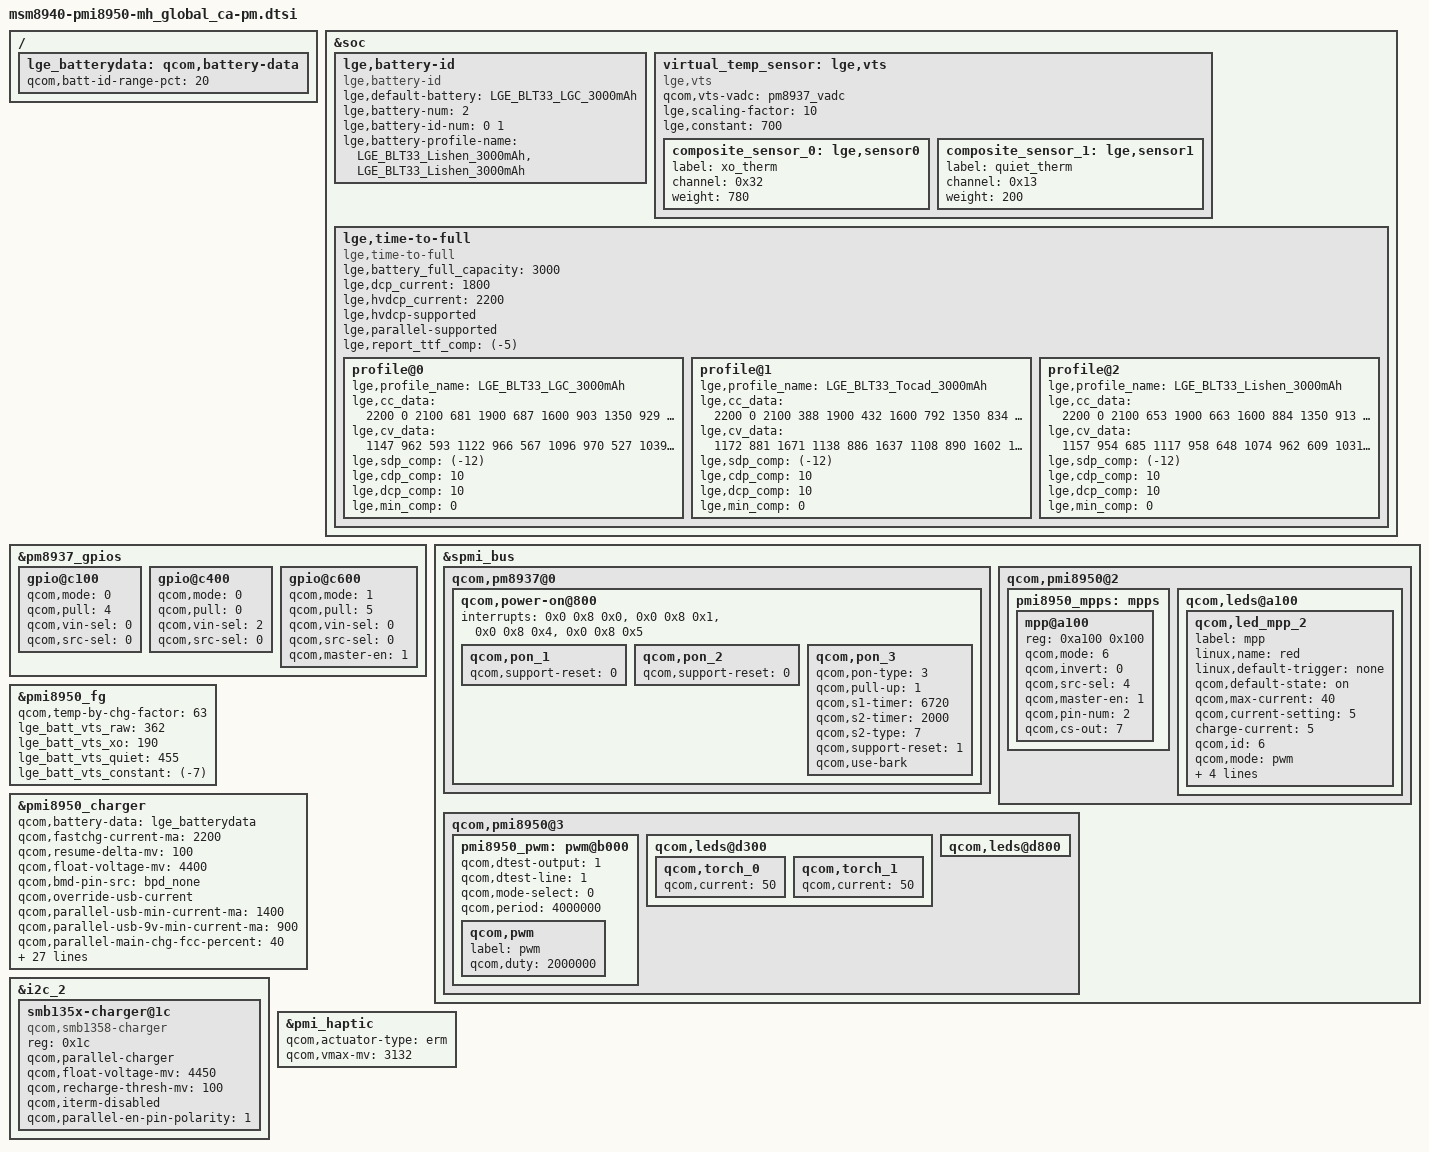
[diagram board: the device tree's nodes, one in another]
/*
 * Copyright (c) 2016, The Linux Foundation. All rights reserved.
 *
 * This program is free software; you can redistribute it and/or modify
 * it under the terms of the GNU General Public License version 2 and
 * only version 2 as published by the Free Software Foundation.
 *
 * This program is distributed in the hope that it will be useful,
 * but WITHOUT ANY WARRANTY; without even the implied warranty of
 * MERCHANTABILITY or FITNESS FOR A PARTICULAR PURPOSE.  See the
 * GNU General Public License for more details.
 */

/{
	lge_batterydata: qcom,battery-data {
		qcom,batt-id-range-pct = <20>;
		#include "../battery_profile/LGE_BLT33_LGC_3000mAh.dtsi"
		#include "../battery_profile/LGE_BLT33_Tocad_3000mAh.dtsi"
		#include "../battery_profile/LGE_BLT33_Lishen_3000mAh.dtsi"
	};
};

&soc {
	lge,battery-id{
		compatible = "lge,battery-id";
		/delete-property/ lge,restrict-mode-enabled;
		/*default battery profile*/
		lge,default-battery = "LGE_BLT33_LGC_3000mAh";
		/*Total number of combined of battery cell and battery id */
		lge,battery-num = <2>;
		/* battery id and battery profile match numbers */
		lge,battery-id-num = <0 1>;
		/* battery profile */
		lge,battery-profile-name = "LGE_BLT33_Lishen_3000mAh",
						"LGE_BLT33_Lishen_3000mAh";
	};

	/* vts = (0.78*xo_therm) + (0.2*quiet_therm) + (0.7) */
	virtual_temp_sensor: lge,vts {
		compatible = "lge,vts";
		qcom,vts-vadc = <&pm8937_vadc>;
		lge,scaling-factor= <10>;
		lge,constant = <700>;
		composite_sensor_0: lge,sensor0 {
			label = "xo_therm";
			channel = <0x32>;
			weight = <780>;
		};
		composite_sensor_1: lge,sensor1 {
			label = "quiet_therm";
			channel = <0x13>;
			weight = <200>;
		};
	};

	/* time to full */
	lge,time-to-full {
		compatible = "lge,time-to-full";
		lge,battery_full_capacity = <3000>;
		lge,dcp_current = <1800>;
		lge,hvdcp_current = <2200>;
		lge,hvdcp-supported;
		lge,parallel-supported;
		lge,report_ttf_comp = <(-5)>;
		profile@0 {
			lge,profile_name = "LGE_BLT33_LGC_3000mAh";
				    /* current  soc */
			lge,cc_data = < 2200	0
					2100	681
					1900	687
					1600	903
					1350	929
					1175	951>;
				    /* current  soc    time */
			lge,cv_data = < 1147	962	593
					1122	966	567
					1096	970	527
					1039	973	486
					993	977	442
					934	980	395
					887	983	347
					745	986	295
					787	989	241
					743	992	184
					709	995	125
					663	998	63
					645	1000	0>;
			lge,sdp_comp = <(-12)>;
			lge,cdp_comp = <10>;
			lge,dcp_comp = <10>;
			lge,min_comp = <0>;
		};
		profile@1 {
			lge,profile_name = "LGE_BLT33_Tocad_3000mAh";
				    /* current  soc */
			lge,cc_data = < 2200	0
					2100	388
					1900	432
					1600	792
					1350	834
					1175	869>;
				    /* current  soc    time */
			lge,cv_data = < 1172	881	1671
					1138	886	1637
					1108	890	1602
					1083	894	1566
					1068	898	1530
					1051	903	1493
					1021	907	1454
					992	911	1414
					962	915	1374
					937	920	1332
					906	924	1289
					878	928	1246
					739	932	1201
					823	937	1154
					795	941	1105
					767	945	1055
					748	949	1003
					728	954	951
					700	958	896
					675	962	840
					650	966	782
					624	970	722
					597	973	662
					517	977	599
					555	980	532
					529	983	464
					506	986	393
					487	989	321
					461	992	246
					442	995	167
					419	998	86
					398	1000	0>;
			lge,sdp_comp = <(-12)>;
			lge,cdp_comp = <10>;
			lge,dcp_comp = <10>;
			lge,min_comp = <0>;
		};
		profile@2 {
			lge,profile_name = "LGE_BLT33_Lishen_3000mAh";
				    /* current  soc */
			lge,cc_data = < 2200	0
					2100	653
					1900	663
					1600	884
					1350	913
					1175	937>;
				    /* current  soc    time */
			lge,cv_data = < 1157	954	685
					1117	958	648
					1074	962	609
					1031	966	570
					986	970	527
					944	973	485
					906	977	439
					856	980	393
					816	983	343
					776	986	292
					750	989	237
					622	992	182
					672	995	122
					658	998	63
					621	1000	0>;
			lge,sdp_comp = <(-12)>;
			lge,cdp_comp = <10>;
			lge,dcp_comp = <10>;
			lge,min_comp = <0>;
		};
	};
};

&pm8937_gpios {
	gpio@c100 {
		qcom,mode = <0>;
		qcom,pull = <4>;
		qcom,vin-sel = <0>;
		qcom,src-sel = <0>;
		status = "okay";
	};
	gpio@c400 {
		qcom,mode = <0>;
		qcom,pull = <0>;
		qcom,vin-sel = <2>;
		qcom,src-sel = <0>;
		status = "okay";
	};
	gpio@c600 {
		status = "okay";
		qcom,mode = <1>;
		qcom,pull = <5>;
		qcom,vin-sel = <0>;
		qcom,src-sel = <0>;
		qcom,master-en = <1>;
	};
};

&spmi_bus {
	qcom,pm8937@0 {
		qcom,power-on@800 {
			interrupts = <0x0 0x8 0x0>,
				     <0x0 0x8 0x1>,
				     <0x0 0x8 0x4>,
				     <0x0 0x8 0x5>;
			interrupt-names = "kpdpwr", "resin",
				"resin-bark", "kpdpwr-resin-bark";

			qcom,pon_1 {
				status = "ok";
				qcom,support-reset = <0>;
			};
			qcom,pon_2 {
				status = "ok";
				qcom,support-reset = <0>;
			};
			qcom,pon_3 {
				status = "ok";
				qcom,pon-type = <3>;
				qcom,pull-up = <1>;
				qcom,s1-timer = <6720>;
				qcom,s2-timer = <2000>;
				qcom,s2-type = <7>;
				qcom,support-reset = <1>;
				qcom,use-bark;
			};
		};
	};

	qcom,pmi8950@2 {
		pmi8950_mpps: mpps {
			mpp@a100 {
				status = "okay";
				reg = <0xa100 0x100>;
				qcom,mode = <6>;
				qcom,invert = <0>;
				qcom,src-sel = <4>;
				qcom,master-en = <1>;
				qcom,pin-num = <2>;
				qcom,cs-out = <7>;
			};
		};
		qcom,leds@a100 {
			status = "okay";
			qcom,led_mpp_2 {
				label = "mpp";
				linux,name = "red";
				linux,default-trigger = "none";
				qcom,default-state = "on";
				qcom,max-current = <40>;
				qcom,current-setting = <5>;
				charge-current = <5>;
				qcom,id = <6>;
				qcom,mode = "pwm";
				qcom,pwm-us = <1000>;
				qcom,source-sel = <8>;
				qcom,mode-ctrl = <0x60>;
				pwms = <&pmi8950_pwm 0 0>;
			};
		};
	};

	qcom,pmi8950@3 {
		pmi8950_pwm: pwm@b000 {
			status = "ok";
			qcom,dtest-output = <1>;
			qcom,dtest-line = <1>;
			qcom,mode-select = <0>;
			qcom,period = <4000000>;
			qcom,pwm {
				label = "pwm";
				qcom,duty = <2000000>;
			};
		};
		qcom,leds@d300 {
			qcom,torch_0 {
				qcom,current = <50>;
			};
			qcom,torch_1 {
				qcom,current = <50>;
			};
		};
		qcom,leds@d800 {
			/delete-property/ qcom,en-ext-pfet-sc-pro;
		};
	};
};

&pmi8950_fg {
	qcom,temp-by-chg-factor = <63>;
	lge_batt_vts_raw = <362>;
	lge_batt_vts_xo = <190>;
	lge_batt_vts_quiet = <455>;
	lge_batt_vts_constant = <(-7)>;
};

&pmi8950_charger {
	qcom,battery-data = <&lge_batterydata>;
	qcom,fastchg-current-ma = <2200>;
	qcom,resume-delta-mv = <100>;
	qcom,float-voltage-mv = <4400>;
	qcom,bmd-pin-src = "bpd_none";
	qcom,override-usb-current;
	qcom,parallel-usb-min-current-ma = <1400>;
	qcom,parallel-usb-9v-min-current-ma = <900>;
	qcom,parallel-main-chg-fcc-percent = <40>;
	qcom,parallel-main-chg-icl-percent = <35>;
	lge,jeita-disabled;
	lge,parallel-supported;

	qcom,usb_pin-vadc = <&pmi8950_vadc>;

	/* ref resistance 200K */
	lge,no-init-cable = <0 0 0>;
	lge,cable-mhl-1k = <5000 500 500>;
	lge,cable-u-28p7k = <10000 1800 500>;
	lge,cable-28p7k = <250000 1800 500>;
	lge,cable-56k = <600000 1500 1500>;
	lge,cable-100k = <620000 1800 500>;
	lge,cable-130k = <780000 1500 1500>;
	lge,cable-180k = <870000 1800 500>;
	lge,cable-200k = <910000 1800 500>;
	lge,cable-220k = <960000 1800 500>;
	lge,cable-270k = <1050000 1800 500>;
	lge,cable-330k = <1150000 1800 500>;
	lge,cable-620k = <1380000 1800 500>;
	lge,cable-910k = <1630000 1500 1500>;
	lge,cable-none = <1900000 1800  500>;

	lge,usb-max-current-ma = <1800>;
	lge,iusb-qc20 = <1800 500>;
	lge,ibat-qc20 = <2200 1000>;
	lge,otp-warm-ibat = <900>;
	lge,otp-cold-ibat = <900>;
	lge,battery-spec-size = <4>;
		lge,battery-spec = <
			0 10 4400 600	/* 0.2C */
			10 20 4400 900	/* 0.3C */
			20 45 4400 2200	/* 0.7C */
			45 60 4400 900	/* 0.3C */
		>;
};

&i2c_2 {
	/* Parallel-charger configuration */
	smb135x-charger@1c{
		compatible = "qcom,smb1358-charger";
		reg = <0x1c>;
		qcom,parallel-charger;
		qcom,float-voltage-mv = <4450>;
		qcom,recharge-thresh-mv = <100>;
		qcom,iterm-disabled;
		qcom,parallel-en-pin-polarity = <1>;
	};
};

&pmi_haptic {
        status = "okay";
        qcom,actuator-type = "erm";
        qcom,vmax-mv = <3132>;
};
